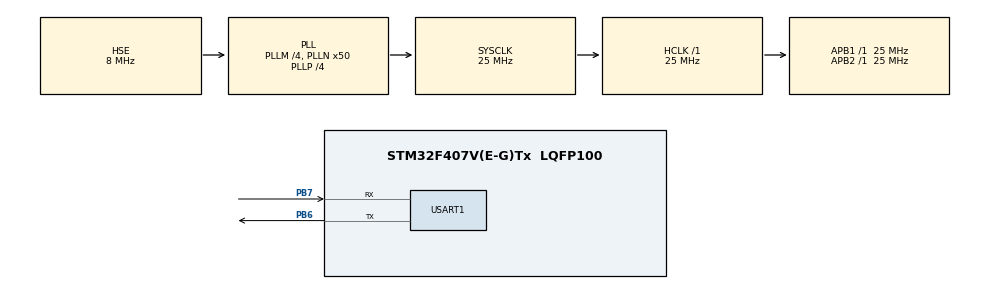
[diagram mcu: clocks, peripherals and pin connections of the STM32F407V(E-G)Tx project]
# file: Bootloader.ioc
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Dma.Request0=USART1_RX
Dma.USART1_RX.0.Direction=DMA_PERIPH_TO_MEMORY
Dma.USART1_RX.0.FIFOMode=DMA_FIFOMODE_DISABLE
Dma.USART1_RX.0.Instance=DMA2_Stream2
Dma.USART1_RX.0.MemDataAlignment=DMA_MDATAALIGN_BYTE
Dma.USART1_RX.0.MemInc=DMA_MINC_ENABLE
Dma.USART1_RX.0.Mode=DMA_NORMAL
Dma.USART1_RX.0.PeriphDataAlignment=DMA_PDATAALIGN_BYTE
Dma.USART1_RX.0.PeriphInc=DMA_PINC_DISABLE
Dma.USART1_RX.0.Priority=DMA_PRIORITY_LOW
IWDG.Prescaler=IWDG_PRESCALER_256
IWDG.Reload=1250
Mcu.Family=STM32F4
Mcu.Name=STM32F407V(E-G)Tx
Mcu.Package=LQFP100
NVIC.DMA2_Stream2_IRQn=true\:0\:0\:false\:false\:true\:false\:true\:true
NVIC.PriorityGroup=NVIC_PRIORITYGROUP_0
NVIC.USART1_IRQn=true\:0\:0\:false\:false\:true\:true\:true\:true
PA13.Mode=Serial_Wire
PA13.Signal=SYS_JTMS-SWDIO
PA14.Mode=Serial_Wire
PA14.Signal=SYS_JTCK-SWCLK
PB6.Mode=Asynchronous
PB6.Signal=USART1_TX
PB7.Mode=Asynchronous
PB7.Signal=USART1_RX
PC14-OSC32_IN.Mode=LSE-External-Oscillator
PC14-OSC32_IN.Signal=RCC_OSC32_IN
PC15-OSC32_OUT.Mode=LSE-External-Oscillator
PC15-OSC32_OUT.Signal=RCC_OSC32_OUT
PH0-OSC_IN.Mode=HSE-External-Oscillator
PH0-OSC_IN.Signal=RCC_OSC_IN
PH1-OSC_OUT.Mode=HSE-External-Oscillator
PH1-OSC_OUT.Signal=RCC_OSC_OUT
ProjectManager.HeapSize=0x200
ProjectManager.StackSize=0x400
ProjectManager.TargetToolchain=STM32CubeIDE
RCC.48MHZClocksFreq_Value=14285714.285714285
RCC.AHBFreq_Value=25000000
RCC.APB1Freq_Value=25000000
RCC.APB1TimFreq_Value=25000000
RCC.APB2Freq_Value=25000000
RCC.APB2TimFreq_Value=25000000
RCC.CortexFreq_Value=25000000
RCC.HCLKFreq_Value=25000000
RCC.HSE_VALUE=8000000
RCC.HSI_VALUE=16000000
RCC.PLLM=4
RCC.PLLN=50
RCC.PLLP=RCC_PLLP_DIV4
RCC.PLLQ=7
RCC.PLLSourceVirtual=RCC_PLLSOURCE_HSE
RCC.SYSCLKFreq_VALUE=25000000
RCC.SYSCLKSource=RCC_SYSCLKSOURCE_PLLCLK
RCC.VCOOutputFreq_Value=100000000
USART1.VirtualMode=VM_ASYNC
VP_CRC_VS_CRC.Mode=CRC_Activate
VP_IWDG_VS_IWDG.Mode=IWDG_Activate
board=STM32F407G-DISC1

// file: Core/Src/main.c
/* USER CODE BEGIN Header */
/**
  ******************************************************************************
  * @file           : main.c
  * @brief          : Main program body
  ******************************************************************************
  * @attention
  *
  * Copyright (c) 2026 STMicroelectronics.
  * All rights reserved.
  *
  * This software is licensed under terms that can be found in the LICENSE file
  * in the root directory of this software component.
  * If no LICENSE file comes with this software, it is provided AS-IS.
  *
  ******************************************************************************
  */
/* USER CODE END Header */
#include "main.h"
#include "crc.h"
#include "dma.h"
#include "iwdg.h"
#include "usart.h"
#include "gpio.h"

/* USER CODE BEGIN Includes */
#include "bootloader.h"
#include "flash.h"
#include "firmware_update.h"
#include <string.h>
/* USER CODE END Includes */

void SystemClock_Config(void);

/* USER CODE BEGIN 0 */
FirmwareProcessData_s FirmwareProcessData;
uint8_t crc_test[] = {0x00, 0x11, 0x22, 0x33, 0x44, 0x55, 0x66, 0x77, 0x70,0x80, 0x84, 0xF4};
uint32_t reset_flag;
uint8_t permit_code[PERMIT_SIZE] = {0xAA, 0xAA, 0xAA, 0xAA, 0xAA};
uint8_t uart_rx_buf[UART_SIZE];
/* USER CODE END 0 */

int main(void)
{

  /* MCU Configuration--------------------------------------------------------*/

  /* Reset of all peripherals, Initializes the Flash interface and the Systick. */
  HAL_Init();

  /* Configure the system clock */
  SystemClock_Config();

  /* USER CODE BEGIN SysInit */
  reset_flag = RCC ->CSR;
  /* USER CODE END SysInit */

  /* Initialize all configured peripherals */
  MX_GPIO_Init();
  MX_DMA_Init();
  MX_CRC_Init();
  MX_USART1_UART_Init();
  MX_IWDG_Init();
  /* USER CODE BEGIN 2 */
  printf("Start Bootloader...\r\n");
  run_bootloader();
  /* USER CODE END 2 */

  /* Infinite loop */
  while (1)
  {

  }
}

void SystemClock_Config(void)
{
  RCC_OscInitTypeDef RCC_OscInitStruct = {0};
  RCC_ClkInitTypeDef RCC_ClkInitStruct = {0};

  /** Configure the main internal regulator output voltage
  */
  __HAL_RCC_PWR_CLK_ENABLE();
  __HAL_PWR_VOLTAGESCALING_CONFIG(PWR_REGULATOR_VOLTAGE_SCALE1);

  /** Initializes the RCC Oscillators according to the specified parameters
  * in the RCC_OscInitTypeDef structure.
  */
  RCC_OscInitStruct.OscillatorType = RCC_OSCILLATORTYPE_LSI|RCC_OSCILLATORTYPE_HSE;
  RCC_OscInitStruct.HSEState = RCC_HSE_ON;
  RCC_OscInitStruct.LSIState = RCC_LSI_ON;
  RCC_OscInitStruct.PLL.PLLState = RCC_PLL_ON;
  RCC_OscInitStruct.PLL.PLLSource = RCC_PLLSOURCE_HSE;
  RCC_OscInitStruct.PLL.PLLM = 4;
  RCC_OscInitStruct.PLL.PLLN = 50;
  RCC_OscInitStruct.PLL.PLLP = RCC_PLLP_DIV4;
  RCC_OscInitStruct.PLL.PLLQ = 7;
  if (HAL_RCC_OscConfig(&RCC_OscInitStruct) != HAL_OK)
  {
    Error_Handler();
  }

  /** Initializes the CPU, AHB and APB buses clocks
  */
  RCC_ClkInitStruct.ClockType = RCC_CLOCKTYPE_HCLK|RCC_CLOCKTYPE_SYSCLK
                              |RCC_CLOCKTYPE_PCLK1|RCC_CLOCKTYPE_PCLK2;
  RCC_ClkInitStruct.SYSCLKSource = RCC_SYSCLKSOURCE_PLLCLK;
  RCC_ClkInitStruct.AHBCLKDivider = RCC_SYSCLK_DIV1;
  RCC_ClkInitStruct.APB1CLKDivider = RCC_HCLK_DIV1;
  RCC_ClkInitStruct.APB2CLKDivider = RCC_HCLK_DIV1;

  if (HAL_RCC_ClockConfig(&RCC_ClkInitStruct, FLASH_LATENCY_0) != HAL_OK)
  {
    Error_Handler();
  }
}

/* USER CODE BEGIN 4 */
int _write(int file, char *ptr, int len)
{
	for (int i = 0; i < len; i++) {
	    ITM_SendChar((*ptr++));
	  }
	  return len;
}

void HAL_UARTEx_RxEventCallback(UART_HandleTypeDef *huart, uint16_t Size)
{
    if (huart->Instance == USART1)
    {
    	if(memcmp(uart_rx_buf, permit_code, PERMIT_SIZE) == 0)
    	{
    		FirmwareProcessData.write_permission = SET;
    	}

    	if (uart_rx_buf[LAST_INDEX - LAST_INDEX] == SOT && uart_rx_buf[LAST_INDEX] == EOT && Size == UART_SIZE)
    	{
    		FirmwareProcessData.processing_data = SET;
    	}

    	if(!FirmwareProcessData.processing_data && !FirmwareProcessData.write_permission)
    	{
    		memset(uart_rx_buf, 0x0, UART_SIZE);
    		HAL_UARTEx_ReceiveToIdle_DMA(&huart1, uart_rx_buf, UART_SIZE);
    		__HAL_DMA_DISABLE_IT(&hdma_usart1_rx, DMA_IT_HT);
    	}
    }
}

/* USER CODE END 4 */

void Error_Handler(void)
{
  __disable_irq();
  while (1)
  {
  }
}
